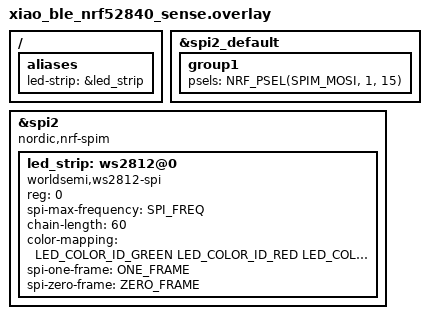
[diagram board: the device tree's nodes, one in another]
/*
 * Copyright (c) 2019, Nordic Semiconductor ASA
 *
 * SPDX-License-Identifier: Apache-2.0
 */

#include <zephyr/dt-bindings/led/led.h>

#include "../nrf52-bindings.h"

&spi2_default {
	group1 {
		psels = <NRF_PSEL(SPIM_MOSI, 1, 15)>;
	};
};

&spi2 { /* MOSI on D10 / P1.15 */
	compatible = "nordic,nrf-spim";
	status = "okay";
	led_strip: ws2812@0 {
		compatible = "worldsemi,ws2812-spi";

		/* SPI */
		reg = <0>; /* ignored, but necessary for SPI bindings */
		spi-max-frequency = <SPI_FREQ>;

		/* WS2812 */
		chain-length = <60>; /* arbitrary; change at will */
		color-mapping = <LED_COLOR_ID_GREEN
				 LED_COLOR_ID_RED
				 LED_COLOR_ID_BLUE>;
		spi-one-frame = <ONE_FRAME>;
		spi-zero-frame = <ZERO_FRAME>;
	};
};

/ {
	aliases {
		led-strip = &led_strip;
	};
};
